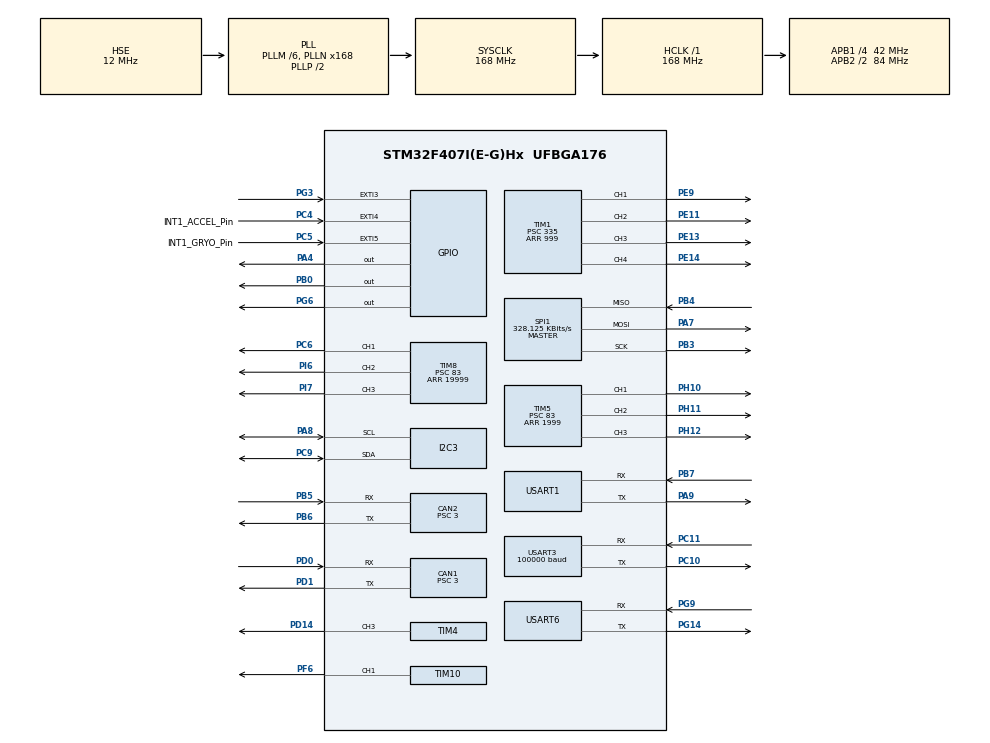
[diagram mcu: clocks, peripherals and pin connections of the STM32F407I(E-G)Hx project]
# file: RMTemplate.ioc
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CAN1.BS1=CAN_BS1_10TQ
CAN1.BS2=CAN_BS2_3TQ
CAN1.CalculateBaudRate=1000000
CAN1.CalculateTimeBit=1000
CAN1.CalculateTimeQuantum=71.42857142857143
CAN1.Prescaler=3
CAN2.BS1=CAN_BS1_10TQ
CAN2.BS2=CAN_BS2_3TQ
CAN2.CalculateBaudRate=1000000
CAN2.CalculateTimeBit=1000
CAN2.CalculateTimeQuantum=71.42857142857143
CAN2.Prescaler=3
Dma.Request0=USART3_RX
Dma.Request1=USART1_TX
Dma.Request2=USART1_RX
Dma.Request3=USART6_RX
Dma.Request4=USART6_TX
Dma.Request5=TIM1_CH1
Dma.Request6=TIM8_CH1/CH2/CH3
Dma.Request7=TIM4_CH3
Dma.Request8=TIM5_CH1
Dma.Request9=TIM5_CH2
Dma.TIM1_CH1.5.Direction=DMA_PERIPH_TO_MEMORY
Dma.TIM1_CH1.5.FIFOMode=DMA_FIFOMODE_DISABLE
Dma.TIM1_CH1.5.Instance=DMA2_Stream3
Dma.TIM1_CH1.5.MemDataAlignment=DMA_MDATAALIGN_HALFWORD
Dma.TIM1_CH1.5.MemInc=DMA_MINC_ENABLE
Dma.TIM1_CH1.5.Mode=DMA_NORMAL
Dma.TIM1_CH1.5.PeriphDataAlignment=DMA_PDATAALIGN_HALFWORD
Dma.TIM1_CH1.5.PeriphInc=DMA_PINC_DISABLE
Dma.TIM1_CH1.5.Priority=DMA_PRIORITY_LOW
Dma.TIM4_CH3.7.Direction=DMA_PERIPH_TO_MEMORY
Dma.TIM4_CH3.7.FIFOMode=DMA_FIFOMODE_DISABLE
Dma.TIM4_CH3.7.Instance=DMA1_Stream7
Dma.TIM4_CH3.7.MemDataAlignment=DMA_MDATAALIGN_HALFWORD
Dma.TIM4_CH3.7.MemInc=DMA_MINC_ENABLE
Dma.TIM4_CH3.7.Mode=DMA_NORMAL
Dma.TIM4_CH3.7.PeriphDataAlignment=DMA_PDATAALIGN_HALFWORD
Dma.TIM4_CH3.7.PeriphInc=DMA_PINC_DISABLE
Dma.TIM4_CH3.7.Priority=DMA_PRIORITY_LOW
Dma.TIM5_CH1.8.Direction=DMA_PERIPH_TO_MEMORY
Dma.TIM5_CH1.8.FIFOMode=DMA_FIFOMODE_DISABLE
Dma.TIM5_CH1.8.Instance=DMA1_Stream2
Dma.TIM5_CH1.8.MemDataAlignment=DMA_MDATAALIGN_WORD
Dma.TIM5_CH1.8.MemInc=DMA_MINC_ENABLE
Dma.TIM5_CH1.8.Mode=DMA_NORMAL
Dma.TIM5_CH1.8.PeriphDataAlignment=DMA_PDATAALIGN_WORD
Dma.TIM5_CH1.8.PeriphInc=DMA_PINC_DISABLE
Dma.TIM5_CH1.8.Priority=DMA_PRIORITY_LOW
Dma.TIM5_CH2.9.Direction=DMA_PERIPH_TO_MEMORY
Dma.TIM5_CH2.9.FIFOMode=DMA_FIFOMODE_DISABLE
Dma.TIM5_CH2.9.Instance=DMA1_Stream4
Dma.TIM5_CH2.9.MemDataAlignment=DMA_MDATAALIGN_WORD
Dma.TIM5_CH2.9.MemInc=DMA_MINC_ENABLE
Dma.TIM5_CH2.9.Mode=DMA_NORMAL
Dma.TIM5_CH2.9.PeriphDataAlignment=DMA_PDATAALIGN_WORD
Dma.TIM5_CH2.9.PeriphInc=DMA_PINC_DISABLE
Dma.TIM5_CH2.9.Priority=DMA_PRIORITY_LOW
Dma.TIM8_CH1/CH2/CH3.6.Direction=DMA_PERIPH_TO_MEMORY
Dma.TIM8_CH1/CH2/CH3.6.FIFOMode=DMA_FIFOMODE_DISABLE
Dma.TIM8_CH1/CH2/CH3.6.Instance=DMA2_Stream2
Dma.TIM8_CH1/CH2/CH3.6.MemDataAlignment=DMA_MDATAALIGN_HALFWORD
Dma.TIM8_CH1/CH2/CH3.6.MemInc=DMA_MINC_ENABLE
Dma.TIM8_CH1/CH2/CH3.6.Mode=DMA_NORMAL
Dma.TIM8_CH1/CH2/CH3.6.PeriphDataAlignment=DMA_PDATAALIGN_HALFWORD
Dma.TIM8_CH1/CH2/CH3.6.PeriphInc=DMA_PINC_DISABLE
Dma.TIM8_CH1/CH2/CH3.6.Priority=DMA_PRIORITY_LOW
Dma.USART1_RX.2.Direction=DMA_PERIPH_TO_MEMORY
Dma.USART1_RX.2.FIFOMode=DMA_FIFOMODE_DISABLE
Dma.USART1_RX.2.Instance=DMA2_Stream5
Dma.USART1_RX.2.MemDataAlignment=DMA_MDATAALIGN_BYTE
Dma.USART1_RX.2.MemInc=DMA_MINC_ENABLE
Dma.USART1_RX.2.Mode=DMA_NORMAL
Dma.USART1_RX.2.PeriphDataAlignment=DMA_PDATAALIGN_BYTE
Dma.USART1_RX.2.PeriphInc=DMA_PINC_DISABLE
Dma.USART1_RX.2.Priority=DMA_PRIORITY_VERY_HIGH
Dma.USART1_TX.1.Direction=DMA_MEMORY_TO_PERIPH
Dma.USART1_TX.1.FIFOMode=DMA_FIFOMODE_DISABLE
Dma.USART1_TX.1.Instance=DMA2_Stream7
Dma.USART1_TX.1.MemDataAlignment=DMA_MDATAALIGN_BYTE
Dma.USART1_TX.1.MemInc=DMA_MINC_ENABLE
Dma.USART1_TX.1.Mode=DMA_NORMAL
Dma.USART1_TX.1.PeriphDataAlignment=DMA_PDATAALIGN_BYTE
Dma.USART1_TX.1.PeriphInc=DMA_PINC_DISABLE
Dma.USART1_TX.1.Priority=DMA_PRIORITY_VERY_HIGH
Dma.USART3_RX.0.Direction=DMA_PERIPH_TO_MEMORY
Dma.USART3_RX.0.FIFOMode=DMA_FIFOMODE_DISABLE
Dma.USART3_RX.0.Instance=DMA1_Stream1
Dma.USART3_RX.0.MemDataAlignment=DMA_MDATAALIGN_BYTE
Dma.USART3_RX.0.MemInc=DMA_MINC_ENABLE
Dma.USART3_RX.0.Mode=DMA_CIRCULAR
Dma.USART3_RX.0.PeriphDataAlignment=DMA_PDATAALIGN_BYTE
Dma.USART3_RX.0.PeriphInc=DMA_PINC_DISABLE
Dma.USART3_RX.0.Priority=DMA_PRIORITY_VERY_HIGH
Dma.USART6_RX.3.Direction=DMA_PERIPH_TO_MEMORY
Dma.USART6_RX.3.FIFOMode=DMA_FIFOMODE_DISABLE
Dma.USART6_RX.3.Instance=DMA2_Stream1
Dma.USART6_RX.3.MemDataAlignment=DMA_MDATAALIGN_BYTE
Dma.USART6_RX.3.MemInc=DMA_MINC_ENABLE
Dma.USART6_RX.3.Mode=DMA_NORMAL
Dma.USART6_RX.3.PeriphDataAlignment=DMA_PDATAALIGN_BYTE
Dma.USART6_RX.3.PeriphInc=DMA_PINC_DISABLE
Dma.USART6_RX.3.Priority=DMA_PRIORITY_VERY_HIGH
Dma.USART6_TX.4.Direction=DMA_MEMORY_TO_PERIPH
Dma.USART6_TX.4.FIFOMode=DMA_FIFOMODE_DISABLE
Dma.USART6_TX.4.Instance=DMA2_Stream6
Dma.USART6_TX.4.MemDataAlignment=DMA_MDATAALIGN_BYTE
Dma.USART6_TX.4.MemInc=DMA_MINC_ENABLE
Dma.USART6_TX.4.Mode=DMA_NORMAL
Dma.USART6_TX.4.PeriphDataAlignment=DMA_PDATAALIGN_BYTE
Dma.USART6_TX.4.PeriphInc=DMA_PINC_DISABLE
Dma.USART6_TX.4.Priority=DMA_PRIORITY_VERY_HIGH
FREERTOS.INCLUDE_pcTaskGetTaskName=1
FREERTOS.INCLUDE_xTaskGetHandle=1
FREERTOS.Tasks01=defaultTask,32,1024,TaskMain,Default,NULL,Dynamic,NULL,NULL;chassisTask,40,1024,TaskChassis,Default,NULL,Dynamic,NULL,NULL;IMUtempPIDtask,24,512,imu_temp_control_task,As weak,NULL,Dynamic,NULL,NULL;turretTask,24,1024,TaskTurret,Default,NULL,Dynamic,NULL,NULL
FREERTOS.configUSE_NEWLIB_REENTRANT=1
I2C3.I2C_Mode=I2C_Fast
Mcu.Family=STM32F4
Mcu.Name=STM32F407I(E-G)Hx
Mcu.Package=UFBGA176
NVIC.CAN1_RX0_IRQn=true\:5\:0\:false\:false\:true\:true\:true\:true\:true
NVIC.CAN2_RX0_IRQn=true\:5\:0\:false\:false\:true\:true\:true\:true\:true
NVIC.DMA1_Stream1_IRQn=true\:5\:0\:false\:false\:true\:true\:false\:true\:true
NVIC.DMA1_Stream2_IRQn=true\:5\:0\:false\:false\:true\:true\:false\:true\:true
NVIC.DMA1_Stream4_IRQn=true\:5\:0\:false\:false\:true\:true\:false\:true\:true
NVIC.DMA1_Stream7_IRQn=true\:5\:0\:false\:false\:true\:true\:false\:true\:true
NVIC.DMA2_Stream1_IRQn=true\:5\:0\:false\:false\:true\:true\:false\:true\:true
NVIC.DMA2_Stream2_IRQn=true\:5\:0\:false\:false\:true\:true\:false\:true\:true
NVIC.DMA2_Stream3_IRQn=true\:5\:0\:false\:false\:true\:true\:false\:true\:true
NVIC.DMA2_Stream5_IRQn=true\:5\:0\:false\:false\:true\:false\:false\:true\:true
NVIC.DMA2_Stream6_IRQn=true\:5\:0\:false\:false\:true\:true\:false\:true\:true
NVIC.DMA2_Stream7_IRQn=true\:5\:0\:false\:false\:true\:true\:false\:true\:true
NVIC.EXTI3_IRQn=true\:5\:0\:false\:false\:true\:true\:true\:true\:true
NVIC.EXTI4_IRQn=true\:5\:0\:false\:false\:true\:true\:true\:true\:true
NVIC.PriorityGroup=NVIC_PRIORITYGROUP_4
NVIC.USART1_IRQn=true\:5\:0\:false\:false\:true\:true\:true\:true\:true
NVIC.USART3_IRQn=true\:5\:0\:false\:false\:false\:true\:true\:true\:true
NVIC.USART6_IRQn=true\:5\:0\:false\:false\:true\:true\:true\:true\:true
PA13.Mode=Serial_Wire
PA13.Signal=SYS_JTMS-SWDIO
PA14.Mode=Serial_Wire
PA14.Signal=SYS_JTCK-SWCLK
PA4.Signal=GPIO_Output
PA7.Mode=Full_Duplex_Master
PA7.Signal=SPI1_MOSI
PA8.Mode=I2C
PA8.Signal=I2C3_SCL
PA9.Mode=Asynchronous
PA9.Signal=USART1_TX
PB0.Signal=GPIO_Output
PB3.Mode=Full_Duplex_Master
PB3.Signal=SPI1_SCK
PB4.Mode=Full_Duplex_Master
PB4.Signal=SPI1_MISO
PB5.Mode=CAN_Activate
PB5.Signal=CAN2_RX
PB6.Mode=CAN_Activate
PB6.Signal=CAN2_TX
PB7.Mode=Asynchronous
PB7.Signal=USART1_RX
PC10.Mode=Asynchronous
PC10.Signal=USART3_TX
PC11.Mode=Asynchronous
PC11.Signal=USART3_RX
PC4.GPIO_Label=INT1_ACCEL_Pin
PC4.Signal=GPXTI4
PC5.GPIO_Label=INT1_GRYO_Pin
PC5.Signal=GPXTI5
PC6.Signal=S_TIM8_CH1
PC9.Mode=I2C
PC9.Signal=I2C3_SDA
PD0.Mode=CAN_Activate
PD0.Signal=CAN1_RX
PD1.Mode=CAN_Activate
PD1.Signal=CAN1_TX
PD14.Signal=S_TIM4_CH3
PE11.Signal=S_TIM1_CH2
PE13.Signal=S_TIM1_CH3
PE14.Signal=S_TIM1_CH4
PE9.Signal=S_TIM1_CH1
PF6.GPIO_PuPd=GPIO_PULLUP
PF6.GPIO_Speed=GPIO_SPEED_FREQ_HIGH
PF6.Signal=S_TIM10_CH1
PG14.Mode=Asynchronous
PG14.Signal=USART6_TX
PG3.Signal=GPXTI3
PG6.Signal=GPIO_Output
PG9.Mode=Asynchronous
PG9.Signal=USART6_RX
PH0-OSC_IN.Mode=HSE-External-Oscillator
PH0-OSC_IN.Signal=RCC_OSC_IN
PH1-OSC_OUT.Mode=HSE-External-Oscillator
PH1-OSC_OUT.Signal=RCC_OSC_OUT
PH10.Signal=S_TIM5_CH1
PH11.Signal=S_TIM5_CH2
PH12.Signal=S_TIM5_CH3
PI6.Signal=S_TIM8_CH2
PI7.Signal=S_TIM8_CH3
ProjectManager.HeapSize=0x200
ProjectManager.StackSize=0x400
ProjectManager.TargetToolchain=STM32CubeIDE
RCC.48MHZClocksFreq_Value=84000000
RCC.AHBFreq_Value=168000000
RCC.APB1CLKDivider=RCC_HCLK_DIV4
RCC.APB1Freq_Value=42000000
RCC.APB1TimFreq_Value=84000000
RCC.APB2CLKDivider=RCC_HCLK_DIV2
RCC.APB2Freq_Value=84000000
RCC.APB2TimFreq_Value=168000000
RCC.CortexFreq_Value=168000000
RCC.EnbaleCSS=true
RCC.HCLKFreq_Value=168000000
RCC.HSE_VALUE=12000000
RCC.HSI_VALUE=16000000
RCC.LSE_VALUE=32768
RCC.PLLM=6
RCC.PLLN=168
RCC.PLLSourceVirtual=RCC_PLLSOURCE_HSE
RCC.SYSCLKFreq_VALUE=168000000
RCC.SYSCLKSource=RCC_SYSCLKSOURCE_PLLCLK
RCC.VCOOutputFreq_Value=336000000
SH.S_TIM10_CH1.0=TIM10_CH1,PWM Generation1 CH1
SH.S_TIM1_CH1.0=TIM1_CH1,PWM Generation1 CH1
SH.S_TIM1_CH2.0=TIM1_CH2,PWM Generation2 CH2
SH.S_TIM1_CH3.0=TIM1_CH3,PWM Generation3 CH3
SH.S_TIM1_CH4.0=TIM1_CH4,PWM Generation4 CH4
SH.S_TIM4_CH3.0=TIM4_CH3,PWM Generation3 CH3
SH.S_TIM5_CH1.0=TIM5_CH1,PWM Generation1 CH1
SH.S_TIM5_CH2.0=TIM5_CH2,PWM Generation2 CH2
SH.S_TIM5_CH3.0=TIM5_CH3,PWM Generation3 CH3
SH.S_TIM8_CH1.0=TIM8_CH1,PWM Generation1 CH1
SH.S_TIM8_CH2.0=TIM8_CH2,PWM Generation2 CH2
SH.S_TIM8_CH3.0=TIM8_CH3,PWM Generation3 CH3
SPI1.BaudRatePrescaler=SPI_BAUDRATEPRESCALER_256
SPI1.CLKPhase=SPI_PHASE_2EDGE
SPI1.CLKPolarity=SPI_POLARITY_HIGH
SPI1.CalculateBaudRate=328.125 KBits/s
SPI1.Direction=SPI_DIRECTION_2LINES
SPI1.Mode=SPI_MODE_MASTER
SPI1.VirtualType=VM_MASTER
TIM1.AutoReloadPreload=TIM_AUTORELOAD_PRELOAD_DISABLE
TIM1.Channel-PWM\ Generation1\ CH1=TIM_CHANNEL_1
TIM1.Channel-PWM\ Generation2\ CH2=TIM_CHANNEL_2
TIM1.Channel-PWM\ Generation3\ CH3=TIM_CHANNEL_3
TIM1.Channel-PWM\ Generation4\ CH4=TIM_CHANNEL_4
TIM1.Period=999
TIM1.Prescaler=335
TIM1.Pulse-PWM\ Generation1\ CH1=0
TIM10.Channel=TIM_CHANNEL_1
TIM10.Period=4999
TIM4.AutoReloadPreload=TIM_AUTORELOAD_PRELOAD_ENABLE
TIM4.Channel-PWM\ Generation3\ CH3=TIM_CHANNEL_3
TIM4.Period=249
TIM4.Prescaler=83
TIM4.Pulse-PWM\ Generation3\ CH3=10499
TIM5.Channel-PWM\ Generation1\ CH1=TIM_CHANNEL_1
TIM5.Channel-PWM\ Generation2\ CH2=TIM_CHANNEL_2
TIM5.Channel-PWM\ Generation3\ CH3=TIM_CHANNEL_3
TIM5.Period=1999
TIM5.Prescaler=83
TIM8.AutoReloadPreload=TIM_AUTORELOAD_PRELOAD_ENABLE
TIM8.Channel-PWM\ Generation1\ CH1=TIM_CHANNEL_1
TIM8.Channel-PWM\ Generation2\ CH2=TIM_CHANNEL_2
TIM8.Channel-PWM\ Generation3\ CH3=TIM_CHANNEL_3
TIM8.Period=19999
TIM8.Prescaler=83
USART1.VirtualMode=VM_ASYNC
USART3.BaudRate=100000
USART3.Parity=PARITY_EVEN
USART3.VirtualMode=VM_ASYNC
USART6.VirtualMode=VM_ASYNC
VP_FREERTOS_VS_CMSIS_V2.Mode=CMSIS_V2
VP_TIM10_VS_ClockSourceINT.Mode=Enable_Timer
VP_TIM4_VS_ClockSourceINT.Mode=Internal
board=custom

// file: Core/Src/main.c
/* USER CODE BEGIN Header */
/**
  ******************************************************************************
  * @file           : main.c
  * @brief          : Main program body
  ******************************************************************************
  * @attention
  *
  * Copyright (c) 2024 STMicroelectronics.
  * All rights reserved.
  *
  * This software is licensed under terms that can be found in the LICENSE file
  * in the root directory of this software component.
  * If no LICENSE file comes with this software, it is provided AS-IS.
  *
  ******************************************************************************
  */
/* USER CODE END Header */
#include "main.h"
#include "cmsis_os.h"

/* USER CODE BEGIN Includes */
#include "CAN_receive.h"
#include "bsp_can.h"
#include "remote_control.h"
#include "bsp_rc.h"
#include "UART.h"
#include "stdio.h"
#include "stdarg.h"
#include "string.h"
#include "BMI088driver.h"
#include "pid.h"
#include "bsp_imu_pwm.h"
#include "ist8310driver.h"
#include "math.h"
#include "ctrl_handling.h"
#include "pwm.h"
/* USER CODE END Includes */

CAN_HandleTypeDef hcan1;
CAN_HandleTypeDef hcan2;

I2C_HandleTypeDef hi2c3;

SPI_HandleTypeDef hspi1;

TIM_HandleTypeDef htim1;
TIM_HandleTypeDef htim4;
TIM_HandleTypeDef htim5;
TIM_HandleTypeDef htim8;
TIM_HandleTypeDef htim10;
DMA_HandleTypeDef hdma_tim1_ch1;
DMA_HandleTypeDef hdma_tim4_ch3;
DMA_HandleTypeDef hdma_tim5_ch1;
DMA_HandleTypeDef hdma_tim5_ch2;
DMA_HandleTypeDef hdma_tim8_ch1_ch2_ch3;

UART_HandleTypeDef huart1;
UART_HandleTypeDef huart3;
UART_HandleTypeDef huart6;
DMA_HandleTypeDef hdma_usart1_tx;
DMA_HandleTypeDef hdma_usart1_rx;
DMA_HandleTypeDef hdma_usart3_rx;
DMA_HandleTypeDef hdma_usart6_rx;
DMA_HandleTypeDef hdma_usart6_tx;

/* Definitions for defaultTask */
osThreadId_t defaultTaskHandle;
const osThreadAttr_t defaultTask_attributes = {
  .name = "defaultTask",
  .stack_size = 1024 * 4,
  .priority = (osPriority_t) osPriorityAboveNormal,
};
/* Definitions for chassisTask */
osThreadId_t chassisTaskHandle;
const osThreadAttr_t chassisTask_attributes = {
  .name = "chassisTask",
  .stack_size = 1024 * 4,
  .priority = (osPriority_t) osPriorityHigh,
};
/* Definitions for IMUtempPIDtask */
osThreadId_t IMUtempPIDtaskHandle;
const osThreadAttr_t IMUtempPIDtask_attributes = {
  .name = "IMUtempPIDtask",
  .stack_size = 512 * 4,
  .priority = (osPriority_t) osPriorityNormal,
};
/* Definitions for turretTask */
osThreadId_t turretTaskHandle;
const osThreadAttr_t turretTask_attributes = {
  .name = "turretTask",
  .stack_size = 1024 * 4,
  .priority = (osPriority_t) osPriorityNormal,
};
/* USER CODE BEGIN PV */
const RC_ctrl_t *local_rc_ctrl;

PID_preset_t chassisPreset = {3.6, 0.015, 4.2};  //0.8f, 0.025f, 0.95f   {1.6, 0.045, 0.10}; 32 0.42
PID_preset_t yawPresetCurrentRPM = {46, 10.0, 16.4};
PID_preset_t yawPresetVoltageRPM = {50, 8.0, 2.0};
PID_preset_t yawPresetCurrentPosition = {12, 1, 0.0};
PID_preset_t yawPresetVoltagePosition = {36, 0.3, 0.0};
PID_preset_t indexerPreset = {1.1f, 0.02f, -2.4f};
PID_preset_t shooterPreset = {1.20f, 0.12f, 1.60f};
PID_preset_t powerPreset = {0, 0.000000000001, 0};
PID_preset_t customPreset = {0, 0, 0};
PID_preset_t DONUTMOTOR = {50, 8.0, 2.0}; // 46, 10, 16.4

int target = 2000;

can_msg_id_e boardID = CAN_b2b_B_ID;               // remember to change the board ID, board A - chassis, board B - Pitch axis

chassis_motor_config chassis = {{1,2,3,4,0,0,0,0}};
chassis_motor_RPM chassisTargetRPM = {{0,0,0,0,0,0,0,0}};
chassis_motor_current chassisTargetCurrent = {{0,0,0,0,0,0,0,0}};

extern game_status_t game_status;
extern power_heat_data_t power_heat_data;
extern robot_status_t robot_status;
extern b2b_motorCtrl_t b2bMotorCtrl;
extern b2b_gyro_t b2bGyro;
extern pc_control_t pc_control;
extern int8_t whichPWMisOn[11];

float calcChassisPower = 0;

/* USER CODE END PV */

void SystemClock_Config(void);
static void MX_GPIO_Init(void);
static void MX_DMA_Init(void);
static void MX_CAN1_Init(void);
static void MX_CAN2_Init(void);
static void MX_SPI1_Init(void);
static void MX_TIM4_Init(void);
static void MX_USART1_UART_Init(void);
static void MX_USART6_UART_Init(void);
static void MX_TIM1_Init(void);
static void MX_TIM8_Init(void);
static void MX_USART3_UART_Init(void);
static void MX_TIM10_Init(void);
static void MX_I2C3_Init(void);
static void MX_TIM5_Init(void);
void TaskMain(void *argument);
void TaskChassis(void *argument);
void imu_temp_control_task(void *argument);
void TaskTurret(void *argument);

int main(void)
{

  /* MCU Configuration--------------------------------------------------------*/

  /* Reset of all peripherals, Initializes the Flash interface and the Systick. */
  HAL_Init();

  /* Configure the system clock */
  SystemClock_Config();

  /* Initialize all configured peripherals */
  MX_GPIO_Init();
  MX_DMA_Init();
  MX_CAN1_Init();
  MX_CAN2_Init();
  MX_SPI1_Init();
  MX_TIM4_Init();
  MX_USART1_UART_Init();
  MX_USART6_UART_Init();
  MX_TIM1_Init();
  MX_TIM8_Init();
  MX_USART3_UART_Init();
  MX_TIM10_Init();
  MX_I2C3_Init();
  MX_TIM5_Init();
  /* USER CODE BEGIN 2 */
  can_filter_init();
  remote_control_init();
  usart_Init();
  local_rc_ctrl = get_remote_control_point();

  //__HAL_UART_ENABLE_IT(&huart1,UART_IT_IDLE);
  /* USER CODE END 2 */
  PWMInit(&htim1, &htim4, &htim5, &htim8);
  /* Init scheduler */
  osKernelInitialize();

  /* Create the thread(s) */
  /* creation of defaultTask */
  defaultTaskHandle = osThreadNew(TaskMain, NULL, &defaultTask_attributes);

  /* creation of chassisTask */
  chassisTaskHandle = osThreadNew(TaskChassis, NULL, &chassisTask_attributes);

  /* creation of IMUtempPIDtask */
  IMUtempPIDtaskHandle = osThreadNew(imu_temp_control_task, NULL, &IMUtempPIDtask_attributes);

  /* creation of turretTask */
  turretTaskHandle = osThreadNew(TaskTurret, NULL, &turretTask_attributes);

  /* Start scheduler */
  osKernelStart();

  /* We should never get here as control is now taken by the scheduler */

  /* Infinite loop */
  while (1)
  {

  }
}

void SystemClock_Config(void)
{
  RCC_OscInitTypeDef RCC_OscInitStruct = {0};
  RCC_ClkInitTypeDef RCC_ClkInitStruct = {0};

  /** Configure the main internal regulator output voltage
  */
  __HAL_RCC_PWR_CLK_ENABLE();
  __HAL_PWR_VOLTAGESCALING_CONFIG(PWR_REGULATOR_VOLTAGE_SCALE1);

  /** Initializes the RCC Oscillators according to the specified parameters
  * in the RCC_OscInitTypeDef structure.
  */
  RCC_OscInitStruct.OscillatorType = RCC_OSCILLATORTYPE_HSE;
  RCC_OscInitStruct.HSEState = RCC_HSE_ON;
  RCC_OscInitStruct.PLL.PLLState = RCC_PLL_ON;
  RCC_OscInitStruct.PLL.PLLSource = RCC_PLLSOURCE_HSE;
  RCC_OscInitStruct.PLL.PLLM = 6;
  RCC_OscInitStruct.PLL.PLLN = 168;
  RCC_OscInitStruct.PLL.PLLP = RCC_PLLP_DIV2;
  RCC_OscInitStruct.PLL.PLLQ = 4;
  if (HAL_RCC_OscConfig(&RCC_OscInitStruct) != HAL_OK)
  {
    Error_Handler();
  }

  /** Initializes the CPU, AHB and APB buses clocks
  */
  RCC_ClkInitStruct.ClockType = RCC_CLOCKTYPE_HCLK|RCC_CLOCKTYPE_SYSCLK
                              |RCC_CLOCKTYPE_PCLK1|RCC_CLOCKTYPE_PCLK2;
  RCC_ClkInitStruct.SYSCLKSource = RCC_SYSCLKSOURCE_PLLCLK;
  RCC_ClkInitStruct.AHBCLKDivider = RCC_SYSCLK_DIV1;
  RCC_ClkInitStruct.APB1CLKDivider = RCC_HCLK_DIV4;
  RCC_ClkInitStruct.APB2CLKDivider = RCC_HCLK_DIV2;

  if (HAL_RCC_ClockConfig(&RCC_ClkInitStruct, FLASH_LATENCY_5) != HAL_OK)
  {
    Error_Handler();
  }

  /** Enables the Clock Security System
  */
  HAL_RCC_EnableCSS();
}

static void MX_CAN1_Init(void)
{

  hcan1.Instance = CAN1;
  hcan1.Init.Prescaler = 3;
  hcan1.Init.Mode = CAN_MODE_NORMAL;
  hcan1.Init.SyncJumpWidth = CAN_SJW_1TQ;
  hcan1.Init.TimeSeg1 = CAN_BS1_10TQ;
  hcan1.Init.TimeSeg2 = CAN_BS2_3TQ;
  hcan1.Init.TimeTriggeredMode = DISABLE;
  hcan1.Init.AutoBusOff = DISABLE;
  hcan1.Init.AutoWakeUp = DISABLE;
  hcan1.Init.AutoRetransmission = DISABLE;
  hcan1.Init.ReceiveFifoLocked = DISABLE;
  hcan1.Init.TransmitFifoPriority = DISABLE;
  if (HAL_CAN_Init(&hcan1) != HAL_OK)
  {
    Error_Handler();
  }

}

static void MX_CAN2_Init(void)
{

  hcan2.Instance = CAN2;
  hcan2.Init.Prescaler = 3;
  hcan2.Init.Mode = CAN_MODE_NORMAL;
  hcan2.Init.SyncJumpWidth = CAN_SJW_1TQ;
  hcan2.Init.TimeSeg1 = CAN_BS1_10TQ;
  hcan2.Init.TimeSeg2 = CAN_BS2_3TQ;
  hcan2.Init.TimeTriggeredMode = DISABLE;
  hcan2.Init.AutoBusOff = DISABLE;
  hcan2.Init.AutoWakeUp = DISABLE;
  hcan2.Init.AutoRetransmission = DISABLE;
  hcan2.Init.ReceiveFifoLocked = DISABLE;
  hcan2.Init.TransmitFifoPriority = DISABLE;
  if (HAL_CAN_Init(&hcan2) != HAL_OK)
  {
    Error_Handler();
  }

}

static void MX_I2C3_Init(void)
{

  hi2c3.Instance = I2C3;
  hi2c3.Init.ClockSpeed = 400000;
  hi2c3.Init.DutyCycle = I2C_DUTYCYCLE_2;
  hi2c3.Init.OwnAddress1 = 0;
  hi2c3.Init.AddressingMode = I2C_ADDRESSINGMODE_7BIT;
  hi2c3.Init.DualAddressMode = I2C_DUALADDRESS_DISABLE;
  hi2c3.Init.OwnAddress2 = 0;
  hi2c3.Init.GeneralCallMode = I2C_GENERALCALL_DISABLE;
  hi2c3.Init.NoStretchMode = I2C_NOSTRETCH_DISABLE;
  if (HAL_I2C_Init(&hi2c3) != HAL_OK)
  {
    Error_Handler();
  }

}

static void MX_SPI1_Init(void)
{

  /* SPI1 parameter configuration*/
  hspi1.Instance = SPI1;
  hspi1.Init.Mode = SPI_MODE_MASTER;
  hspi1.Init.Direction = SPI_DIRECTION_2LINES;
  hspi1.Init.DataSize = SPI_DATASIZE_8BIT;
  hspi1.Init.CLKPolarity = SPI_POLARITY_HIGH;
  hspi1.Init.CLKPhase = SPI_PHASE_2EDGE;
  hspi1.Init.NSS = SPI_NSS_SOFT;
  hspi1.Init.BaudRatePrescaler = SPI_BAUDRATEPRESCALER_256;
  hspi1.Init.FirstBit = SPI_FIRSTBIT_MSB;
  hspi1.Init.TIMode = SPI_TIMODE_DISABLE;
  hspi1.Init.CRCCalculation = SPI_CRCCALCULATION_DISABLE;
  hspi1.Init.CRCPolynomial = 10;
  if (HAL_SPI_Init(&hspi1) != HAL_OK)
  {
    Error_Handler();
  }

}

static void MX_TIM1_Init(void)
{

  TIM_MasterConfigTypeDef sMasterConfig = {0};
  TIM_OC_InitTypeDef sConfigOC = {0};
  TIM_BreakDeadTimeConfigTypeDef sBreakDeadTimeConfig = {0};

  htim1.Instance = TIM1;
  htim1.Init.Prescaler = 335;
  htim1.Init.CounterMode = TIM_COUNTERMODE_UP;
  htim1.Init.Period = 999;
  htim1.Init.ClockDivision = TIM_CLOCKDIVISION_DIV1;
  htim1.Init.RepetitionCounter = 0;
  htim1.Init.AutoReloadPreload = TIM_AUTORELOAD_PRELOAD_DISABLE;
  if (HAL_TIM_PWM_Init(&htim1) != HAL_OK)
  {
    Error_Handler();
  }
  sMasterConfig.MasterOutputTrigger = TIM_TRGO_RESET;
  sMasterConfig.MasterSlaveMode = TIM_MASTERSLAVEMODE_DISABLE;
  if (HAL_TIMEx_MasterConfigSynchronization(&htim1, &sMasterConfig) != HAL_OK)
  {
    Error_Handler();
  }
  sConfigOC.OCMode = TIM_OCMODE_PWM1;
  sConfigOC.Pulse = 0;
  sConfigOC.OCPolarity = TIM_OCPOLARITY_HIGH;
  sConfigOC.OCNPolarity = TIM_OCNPOLARITY_HIGH;
  sConfigOC.OCFastMode = TIM_OCFAST_DISABLE;
  sConfigOC.OCIdleState = TIM_OCIDLESTATE_RESET;
  sConfigOC.OCNIdleState = TIM_OCNIDLESTATE_RESET;
  if (HAL_TIM_PWM_ConfigChannel(&htim1, &sConfigOC, TIM_CHANNEL_1) != HAL_OK)
  {
    Error_Handler();
  }
  if (HAL_TIM_PWM_ConfigChannel(&htim1, &sConfigOC, TIM_CHANNEL_2) != HAL_OK)
  {
    Error_Handler();
  }
  if (HAL_TIM_PWM_ConfigChannel(&htim1, &sConfigOC, TIM_CHANNEL_3) != HAL_OK)
  {
    Error_Handler();
  }
  if (HAL_TIM_PWM_ConfigChannel(&htim1, &sConfigOC, TIM_CHANNEL_4) != HAL_OK)
  {
    Error_Handler();
  }
  sBreakDeadTimeConfig.OffStateRunMode = TIM_OSSR_DISABLE;
  sBreakDeadTimeConfig.OffStateIDLEMode = TIM_OSSI_DISABLE;
  sBreakDeadTimeConfig.LockLevel = TIM_LOCKLEVEL_OFF;
  sBreakDeadTimeConfig.DeadTime = 0;
  sBreakDeadTimeConfig.BreakState = TIM_BREAK_DISABLE;
  sBreakDeadTimeConfig.BreakPolarity = TIM_BREAKPOLARITY_HIGH;
  sBreakDeadTimeConfig.AutomaticOutput = TIM_AUTOMATICOUTPUT_DISABLE;
  if (HAL_TIMEx_ConfigBreakDeadTime(&htim1, &sBreakDeadTimeConfig) != HAL_OK)
  {
    Error_Handler();
  }
  HAL_TIM_MspPostInit(&htim1);

}

static void MX_TIM4_Init(void)
{

  TIM_ClockConfigTypeDef sClockSourceConfig = {0};
  TIM_MasterConfigTypeDef sMasterConfig = {0};
  TIM_OC_InitTypeDef sConfigOC = {0};

  htim4.Instance = TIM4;
  htim4.Init.Prescaler = 83;
  htim4.Init.CounterMode = TIM_COUNTERMODE_UP;
  htim4.Init.Period = 249;
  htim4.Init.ClockDivision = TIM_CLOCKDIVISION_DIV1;
  htim4.Init.AutoReloadPreload = TIM_AUTORELOAD_PRELOAD_ENABLE;
  if (HAL_TIM_Base_Init(&htim4) != HAL_OK)
  {
    Error_Handler();
  }
  sClockSourceConfig.ClockSource = TIM_CLOCKSOURCE_INTERNAL;
  if (HAL_TIM_ConfigClockSource(&htim4, &sClockSourceConfig) != HAL_OK)
  {
    Error_Handler();
  }
  if (HAL_TIM_PWM_Init(&htim4) != HAL_OK)
  {
    Error_Handler();
  }
  sMasterConfig.MasterOutputTrigger = TIM_TRGO_RESET;
  sMasterConfig.MasterSlaveMode = TIM_MASTERSLAVEMODE_DISABLE;
  if (HAL_TIMEx_MasterConfigSynchronization(&htim4, &sMasterConfig) != HAL_OK)
  {
    Error_Handler();
  }
  sConfigOC.OCMode = TIM_OCMODE_PWM1;
  sConfigOC.Pulse = 10499;
  sConfigOC.OCPolarity = TIM_OCPOLARITY_HIGH;
  sConfigOC.OCFastMode = TIM_OCFAST_DISABLE;
  if (HAL_TIM_PWM_ConfigChannel(&htim4, &sConfigOC, TIM_CHANNEL_3) != HAL_OK)
  {
    Error_Handler();
  }
  HAL_TIM_MspPostInit(&htim4);

}

static void MX_TIM5_Init(void)
{

  TIM_MasterConfigTypeDef sMasterConfig = {0};
  TIM_OC_InitTypeDef sConfigOC = {0};

  htim5.Instance = TIM5;
  htim5.Init.Prescaler = 83;
  htim5.Init.CounterMode = TIM_COUNTERMODE_UP;
  htim5.Init.Period = 1999;
  htim5.Init.ClockDivision = TIM_CLOCKDIVISION_DIV1;
  htim5.Init.AutoReloadPreload = TIM_AUTORELOAD_PRELOAD_DISABLE;
  if (HAL_TIM_PWM_Init(&htim5) != HAL_OK)
  {
    Error_Handler();
  }
  sMasterConfig.MasterOutputTrigger = TIM_TRGO_RESET;
  sMasterConfig.MasterSlaveMode = TIM_MASTERSLAVEMODE_DISABLE;
  if (HAL_TIMEx_MasterConfigSynchronization(&htim5, &sMasterConfig) != HAL_OK)
  {
    Error_Handler();
  }
  sConfigOC.OCMode = TIM_OCMODE_PWM1;
  sConfigOC.Pulse = 0;
  sConfigOC.OCPolarity = TIM_OCPOLARITY_HIGH;
  sConfigOC.OCFastMode = TIM_OCFAST_DISABLE;
  if (HAL_TIM_PWM_ConfigChannel(&htim5, &sConfigOC, TIM_CHANNEL_1) != HAL_OK)
  {
    Error_Handler();
  }
  if (HAL_TIM_PWM_ConfigChannel(&htim5, &sConfigOC, TIM_CHANNEL_2) != HAL_OK)
  {
    Error_Handler();
  }
  if (HAL_TIM_PWM_ConfigChannel(&htim5, &sConfigOC, TIM_CHANNEL_3) != HAL_OK)
  {
    Error_Handler();
  }
  HAL_TIM_MspPostInit(&htim5);

}

static void MX_TIM8_Init(void)
{

  TIM_MasterConfigTypeDef sMasterConfig = {0};
  TIM_OC_InitTypeDef sConfigOC = {0};
  TIM_BreakDeadTimeConfigTypeDef sBreakDeadTimeConfig = {0};

  htim8.Instance = TIM8;
  htim8.Init.Prescaler = 83;
  htim8.Init.CounterMode = TIM_COUNTERMODE_UP;
  htim8.Init.Period = 19999;
  htim8.Init.ClockDivision = TIM_CLOCKDIVISION_DIV1;
  htim8.Init.RepetitionCounter = 0;
  htim8.Init.AutoReloadPreload = TIM_AUTORELOAD_PRELOAD_ENABLE;
  if (HAL_TIM_PWM_Init(&htim8) != HAL_OK)
  {
    Error_Handler();
  }
  sMasterConfig.MasterOutputTrigger = TIM_TRGO_RESET;
  sMasterConfig.MasterSlaveMode = TIM_MASTERSLAVEMODE_DISABLE;
  if (HAL_TIMEx_MasterConfigSynchronization(&htim8, &sMasterConfig) != HAL_OK)
  {
    Error_Handler();
  }
  sConfigOC.OCMode = TIM_OCMODE_PWM1;
  sConfigOC.Pulse = 0;
  sConfigOC.OCPolarity = TIM_OCPOLARITY_HIGH;
  sConfigOC.OCNPolarity = TIM_OCNPOLARITY_HIGH;
  sConfigOC.OCFastMode = TIM_OCFAST_DISABLE;
  sConfigOC.OCIdleState = TIM_OCIDLESTATE_RESET;
  sConfigOC.OCNIdleState = TIM_OCNIDLESTATE_RESET;
  if (HAL_TIM_PWM_ConfigChannel(&htim8, &sConfigOC, TIM_CHANNEL_1) != HAL_OK)
  {
    Error_Handler();
  }
  if (HAL_TIM_PWM_ConfigChannel(&htim8, &sConfigOC, TIM_CHANNEL_2) != HAL_OK)
  {
    Error_Handler();
  }
  if (HAL_TIM_PWM_ConfigChannel(&htim8, &sConfigOC, TIM_CHANNEL_3) != HAL_OK)
  {
    Error_Handler();
  }
  sBreakDeadTimeConfig.OffStateRunMode = TIM_OSSR_DISABLE;
  sBreakDeadTimeConfig.OffStateIDLEMode = TIM_OSSI_DISABLE;
  sBreakDeadTimeConfig.LockLevel = TIM_LOCKLEVEL_OFF;
  sBreakDeadTimeConfig.DeadTime = 0;
  sBreakDeadTimeConfig.BreakState = TIM_BREAK_DISABLE;
  sBreakDeadTimeConfig.BreakPolarity = TIM_BREAKPOLARITY_HIGH;
  sBreakDeadTimeConfig.AutomaticOutput = TIM_AUTOMATICOUTPUT_DISABLE;
  if (HAL_TIMEx_ConfigBreakDeadTime(&htim8, &sBreakDeadTimeConfig) != HAL_OK)
  {
    Error_Handler();
  }
  HAL_TIM_MspPostInit(&htim8);

}

static void MX_TIM10_Init(void)
{

  TIM_OC_InitTypeDef sConfigOC = {0};

  htim10.Instance = TIM10;
  htim10.Init.Prescaler = 0;
  htim10.Init.CounterMode = TIM_COUNTERMODE_UP;
  htim10.Init.Period = 4999;
  htim10.Init.ClockDivision = TIM_CLOCKDIVISION_DIV1;
  htim10.Init.AutoReloadPreload = TIM_AUTORELOAD_PRELOAD_DISABLE;
  if (HAL_TIM_Base_Init(&htim10) != HAL_OK)
  {
    Error_Handler();
  }
  if (HAL_TIM_PWM_Init(&htim10) != HAL_OK)
  {
    Error_Handler();
  }
  sConfigOC.OCMode = TIM_OCMODE_PWM1;
  sConfigOC.Pulse = 0;
  sConfigOC.OCPolarity = TIM_OCPOLARITY_HIGH;
  sConfigOC.OCFastMode = TIM_OCFAST_DISABLE;
  if (HAL_TIM_PWM_ConfigChannel(&htim10, &sConfigOC, TIM_CHANNEL_1) != HAL_OK)
  {
    Error_Handler();
  }
  HAL_TIM_MspPostInit(&htim10);

}

static void MX_USART1_UART_Init(void)
{

  huart1.Instance = USART1;
  huart1.Init.BaudRate = 115200;
  huart1.Init.WordLength = UART_WORDLENGTH_8B;
  huart1.Init.StopBits = UART_STOPBITS_1;
  huart1.Init.Parity = UART_PARITY_NONE;
  huart1.Init.Mode = UART_MODE_TX_RX;
  huart1.Init.HwFlowCtl = UART_HWCONTROL_NONE;
  huart1.Init.OverSampling = UART_OVERSAMPLING_16;
  if (HAL_UART_Init(&huart1) != HAL_OK)
  {
    Error_Handler();
  }

}

static void MX_USART3_UART_Init(void)
{

  huart3.Instance = USART3;
  huart3.Init.BaudRate = 100000;
  huart3.Init.WordLength = UART_WORDLENGTH_8B;
  huart3.Init.StopBits = UART_STOPBITS_1;
  huart3.Init.Parity = UART_PARITY_EVEN;
  huart3.Init.Mode = UART_MODE_TX_RX;
  huart3.Init.HwFlowCtl = UART_HWCONTROL_NONE;
  huart3.Init.OverSampling = UART_OVERSAMPLING_16;
  if (HAL_UART_Init(&huart3) != HAL_OK)
  {
    Error_Handler();
  }

}

static void MX_USART6_UART_Init(void)
{

  huart6.Instance = USART6;
  huart6.Init.BaudRate = 115200;
  huart6.Init.WordLength = UART_WORDLENGTH_8B;
  huart6.Init.StopBits = UART_STOPBITS_1;
  huart6.Init.Parity = UART_PARITY_NONE;
  huart6.Init.Mode = UART_MODE_TX_RX;
  huart6.Init.HwFlowCtl = UART_HWCONTROL_NONE;
  huart6.Init.OverSampling = UART_OVERSAMPLING_16;
  if (HAL_UART_Init(&huart6) != HAL_OK)
  {
    Error_Handler();
  }

}

static void MX_DMA_Init(void)
{

  /* DMA controller clock enable */
  __HAL_RCC_DMA1_CLK_ENABLE();
  __HAL_RCC_DMA2_CLK_ENABLE();

  /* DMA interrupt init */
  /* DMA1_Stream1_IRQn interrupt configuration */
  HAL_NVIC_SetPriority(DMA1_Stream1_IRQn, 5, 0);
  HAL_NVIC_EnableIRQ(DMA1_Stream1_IRQn);
  /* DMA1_Stream2_IRQn interrupt configuration */
  HAL_NVIC_SetPriority(DMA1_Stream2_IRQn, 5, 0);
  HAL_NVIC_EnableIRQ(DMA1_Stream2_IRQn);
  /* DMA1_Stream4_IRQn interrupt configuration */
  HAL_NVIC_SetPriority(DMA1_Stream4_IRQn, 5, 0);
  HAL_NVIC_EnableIRQ(DMA1_Stream4_IRQn);
  /* DMA1_Stream7_IRQn interrupt configuration */
  HAL_NVIC_SetPriority(DMA1_Stream7_IRQn, 5, 0);
  HAL_NVIC_EnableIRQ(DMA1_Stream7_IRQn);
  /* DMA2_Stream1_IRQn interrupt configuration */
  HAL_NVIC_SetPriority(DMA2_Stream1_IRQn, 5, 0);
  HAL_NVIC_EnableIRQ(DMA2_Stream1_IRQn);
  /* DMA2_Stream2_IRQn interrupt configuration */
  HAL_NVIC_SetPriority(DMA2_Stream2_IRQn, 5, 0);
  HAL_NVIC_EnableIRQ(DMA2_Stream2_IRQn);
  /* DMA2_Stream3_IRQn interrupt configuration */
  HAL_NVIC_SetPriority(DMA2_Stream3_IRQn, 5, 0);
  HAL_NVIC_EnableIRQ(DMA2_Stream3_IRQn);
  /* DMA2_Stream5_IRQn interrupt configuration */
  HAL_NVIC_SetPriority(DMA2_Stream5_IRQn, 5, 0);
  HAL_NVIC_EnableIRQ(DMA2_Stream5_IRQn);
  /* DMA2_Stream6_IRQn interrupt configuration */
  HAL_NVIC_SetPriority(DMA2_Stream6_IRQn, 5, 0);
  HAL_NVIC_EnableIRQ(DMA2_Stream6_IRQn);
  /* DMA2_Stream7_IRQn interrupt configuration */
  HAL_NVIC_SetPriority(DMA2_Stream7_IRQn, 5, 0);
  HAL_NVIC_EnableIRQ(DMA2_Stream7_IRQn);

}

static void MX_GPIO_Init(void)
{
  GPIO_InitTypeDef GPIO_InitStruct = {0};

  /* GPIO Ports Clock Enable */
  __HAL_RCC_GPIOB_CLK_ENABLE();
  __HAL_RCC_GPIOG_CLK_ENABLE();
  __HAL_RCC_GPIOA_CLK_ENABLE();
  __HAL_RCC_GPIOD_CLK_ENABLE();
  __HAL_RCC_GPIOC_CLK_ENABLE();
  __HAL_RCC_GPIOI_CLK_ENABLE();
  __HAL_RCC_GPIOH_CLK_ENABLE();
  __HAL_RCC_GPIOF_CLK_ENABLE();
  __HAL_RCC_GPIOE_CLK_ENABLE();

  /*Configure GPIO pin Output Level */
  HAL_GPIO_WritePin(GPIOG, GPIO_PIN_6, GPIO_PIN_RESET);

  /*Configure GPIO pin Output Level */
  HAL_GPIO_WritePin(GPIOA, GPIO_PIN_4, GPIO_PIN_RESET);

  /*Configure GPIO pin Output Level */
  HAL_GPIO_WritePin(GPIOB, GPIO_PIN_0, GPIO_PIN_RESET);

  /*Configure GPIO pin : PG6 */
  GPIO_InitStruct.Pin = GPIO_PIN_6;
  GPIO_InitStruct.Mode = GPIO_MODE_OUTPUT_PP;
  GPIO_InitStruct.Pull = GPIO_NOPULL;
  GPIO_InitStruct.Speed = GPIO_SPEED_FREQ_LOW;
  HAL_GPIO_Init(GPIOG, &GPIO_InitStruct);

  /*Configure GPIO pin : PG3 */
  GPIO_InitStruct.Pin = GPIO_PIN_3;
  GPIO_InitStruct.Mode = GPIO_MODE_IT_RISING;
  GPIO_InitStruct.Pull = GPIO_NOPULL;
  HAL_GPIO_Init(GPIOG, &GPIO_InitStruct);

  /*Configure GPIO pin : PA4 */
  GPIO_InitStruct.Pin = GPIO_PIN_4;
  GPIO_InitStruct.Mode = GPIO_MODE_OUTPUT_PP;
  GPIO_InitStruct.Pull = GPIO_NOPULL;
  GPIO_InitStruct.Speed = GPIO_SPEED_FREQ_LOW;
  HAL_GPIO_Init(GPIOA, &GPIO_InitStruct);

  /*Configure GPIO pins : INT1_ACCEL_Pin_Pin INT1_GRYO_Pin_Pin */
  GPIO_InitStruct.Pin = INT1_ACCEL_Pin_Pin|INT1_GRYO_Pin_Pin;
  GPIO_InitStruct.Mode = GPIO_MODE_IT_RISING;
  GPIO_InitStruct.Pull = GPIO_NOPULL;
  HAL_GPIO_Init(GPIOC, &GPIO_InitStruct);

  /*Configure GPIO pin : PB0 */
  GPIO_InitStruct.Pin = GPIO_PIN_0;
  GPIO_InitStruct.Mode = GPIO_MODE_OUTPUT_PP;
  GPIO_InitStruct.Pull = GPIO_NOPULL;
  GPIO_InitStruct.Speed = GPIO_SPEED_FREQ_LOW;
  HAL_GPIO_Init(GPIOB, &GPIO_InitStruct);

  /* EXTI interrupt init*/
  HAL_NVIC_SetPriority(EXTI3_IRQn, 5, 0);
  HAL_NVIC_EnableIRQ(EXTI3_IRQn);

  HAL_NVIC_SetPriority(EXTI4_IRQn, 5, 0);
  HAL_NVIC_EnableIRQ(EXTI4_IRQn);

}

/* USER CODE BEGIN 4 */
int16_t positionPIDByMe(int16_t *prevDiff, int8_t *isNegativeRegion1, int8_t *previousRegion1, int16_t DifferenceBetweenCurrentAndWannabePosition, int16_t *sumI1, float kPu, float kIu, float kDu) {
	if (DifferenceBetweenCurrentAndWannabePosition >= 0) {
		*isNegativeRegion1 = -1;
	} else {
		*isNegativeRegion1 = 1;
	}
	if (*isNegativeRegion1 != *previousRegion1) {
		*sumI1 = 0;
	}
	*previousRegion1 = *isNegativeRegion1;
	*sumI1 += (int)((float)(DifferenceBetweenCurrentAndWannabePosition)*0.005f);
	int16_t PositionToGo = (int)(kPu*(float)(DifferenceBetweenCurrentAndWannabePosition));
	int16_t IntegralToGo = (int)(kIu*((float)(*sumI1)));
	int16_t DerivativeToGo = (int)((kDu)*((float)(DifferenceBetweenCurrentAndWannabePosition - *prevDiff))*(float)200);
	*prevDiff = DifferenceBetweenCurrentAndWannabePosition;
	return PositionToGo+IntegralToGo+DerivativeToGo;
}
/* USER CODE END 4 */

void TaskMain(void *argument)
{
  /* USER CODE BEGIN 5 */
  /* Infinite loop */
	// HAL_GPIO_WritePin(GPIOH, GPIO_PIN_10, 1);
	// __HAL_TIM_PRESCALER(&htim4, 2);
	// HAL_TIM_PWM_Start(&htim4, TIM_CHANNEL_3);
	// HAL_TIM_Base_Start(&htim4);
	if (BMI088_accel_init()) {
		// usart_printf("WARNING - BMI088 accelerometer init failed \r\n");
	}
	if (BMI088_gyro_init()) {
		// usart_printf("WARNING - BMI088 gyroscope init failed \r\n");
	}
	if (ist8310_init()) {
		// usart_printf("WARNING - IST8310 compass init failed \r\n");
	}
	// (htim5).Instance->CCR2=999;
	// osDelay(150);
	// __HAL_TIM_PRESCALER(&htim4, 0);
	// osDelay(150);
	// HAL_TIM_PWM_Stop(&htim4, TIM_CHANNEL_3);
	for(;;) {
		// HAL_GPIO_WritePin(GPIOH, GPIO_PIN_10, 0);
		//set_motor_voltage(5, 4000);

		// HAL_TIM_PWM_Start(&htim5, TIM_CHANNEL_2);

		// PWMOn(LED,1);
		PWMOutput(LED, 1, 500);
		PWMInitialize(LED, FR, 1, 0.9);
		// PWMTimerStarter();
		usart_printf("on\r\n");
		osDelay(500);
		//sendB2bData(CAN_b2b_A_ID, 1, 1, 1, 1);
		// HAL_GPIO_WritePin(GPIOH, GPIO_PIN_10, 1);
		//set_motor_voltage(5, -4000);
		// HAL_TIM_PWM_Stop(&htim5, TIM_CHANNEL_2);
		PWMOff(LED, 1);
		// PWMTimerStarter();
		usart_printf("off\r\n");
		osDelay(500);
		//sendB2bData(CAN_b2b_A_ID, 0, 0, 0, 0);
		//usart_printf("ACTIVE = %d \r\n", power_heat_data.chassis_power);
	}
  /* USER CODE END 5 */
}

void TaskChassis(void *argument)
{
  /* USER CODE BEGIN TaskChassis */
	/* USER CODE BEGIN TaskChassis */
	int16_t rcRPM[4] = {0,0,0,0};                              // maps rc percentage reading to motors, assuming we're running M3508s at max 469RPM
	int16_t rcPitch = 0;                                   // range: 3376 ~ 2132
	//int16_t targetRPM[4] = {0,0,0,0};
  /* Infinite loop */

	// Test Code
	/*
	HAL_TIM_Base_Start(&htim1);
	HAL_TIM_Base_Start(&htim4);
	HAL_TIM_PWM_Start(&htim1, TIM_CHANNEL_1);
	HAL_TIM_PWM_Start(&htim1, TIM_CHANNEL_2);
	HAL_TIM_PWM_Start(&htim4, TIM_CHANNEL_3);
	htim4.Instance->CCR3=0;
	*/

	int8_t motorOn = 0;
	int8_t switched = 0;
	int8_t shot1Round = 0;
	//int8_t RNC = 0;
	int16_t sumI1 =0;
	int16_t sumI2 =0;
	int16_t sumI3 =0;
	int16_t sumI4 =0;
	int8_t isNegativeRegion1 = 0;
	int8_t isNegativeRegion2 = 0;
	int8_t isNegativeRegion3 = 0;
	int8_t isNegativeRegion4 = 0;
	int8_t previousRegion1 = 0;
	int8_t previousRegion2 = 0;
	int8_t previousRegion3 = 0;
	int8_t previousRegion4 = 0;
	int16_t prevDiff1 = 0;
	int16_t prevDiff2 = 0;
	int16_t prevDiff3 = 0;
	int16_t prevDiff4 = 0;

	int16_t shooterMotor = 0;
	// int16_t pR = 0;
	//int8_t counter = 0;
	uint16_t testmotor = 6161;
	uint16_t pivoter = 0;
	double angle = 0;
	int16_t xJoystickDirection = 0;
	int16_t yJoystickDirection = 0;
	int16_t rotationOfChassis = 0;
	// Total Rotation is 1.25 times for 90degrees therefore motor has to rotate
	// PID onto this (This is the hypothetical orientation)
	int16_t chassisOrientation = 0;
	int16_t chassisPID = 0;
	int16_t rcVal2 = 0;

	int16_t randomOrientations[24] = {-380, -202, 462, -114, 240, -210, 150, 170, 248, 106, 118, 538, -260, -288, -120, 86, -264, 452, -592, 390, -410, 414, 54, -542};
	int16_t startingVal = 0;
	int8_t started = 0;
	uint8_t increment = 0;
	int16_t instancesCounter = 0;

	int16_t previousVal = 0;
	int32_t rotationalVal = 0;
	int16_t revolutions = 0;
	int8_t resetPerStart = 0;
	int32_t rotationTarget = 0;
	int32_t posForGunMotor = 0;
	int8_t burst = 3;

	int8_t customFiringModeSwitcher = 0;
	int8_t startedChecking = 0;
	int8_t switchedDown = 0;
	int8_t finalTHing = 0;
	int16_t counterForSwitching = 0;

	int16_t buzzLengthCounter = 0;
	int8_t beepingInProgress = 0;
	int8_t beeped = 1;

	int16_t rotationCompStab = 0;
	int16_t testTHing[11] = {0, 0, 0, 0, 0, 0, 0, 0, 0, 0, 0};

	/*
	float rotationPositionZ = 0;
	float rotationPositionY = 0;
	int8_t average = 5;
	int16_t averageY[average];
	for (int i = 0; i < average; i++) {
		averageY[i] = 0;
	}
	*/

	for(;;) {

		for (int i = 0; i < 4; i++) {
			rcRPM[i] = getRCchannel(i) * 13.645f;              // 13.645 = 469 / 187 / 660 * 3591, 660 = max reading in one direction
		}
		/*
		int arrayOfMOvement[2] = {0, 0};
		getKeyboardVelocity(arrayOfMOvement, 0.03, pc_control);
		rcRPM[0] = 0;
		rcRPM[1] = 0;
		rcRPM[2] = arrayOfMOvement[0];
		rcRPM[3] = arrayOfMOvement[1];
		*/
		rcPitch = getRCchannel(1) * 0.94f + 2754;
		int16_t leftDial = getRCchannel(4);

		int8_t chassisTurning = getRCswitch(1);

		float funnyKP = 0.022;
		float funnyKI = -0.02;
		float funnyKD = 0.00005;
		float rotationScalar = -540; //-540

		if (counterForSwitching > 200) {
			startedChecking = 0;
			switchedDown = 0;
			finalTHing = 0;
			counterForSwitching = 0;
		}

		if (startedChecking == 1) {
			counterForSwitching++;
		}

		int8_t movementUpOrDown = 5;
		if (increment == 18) {
			increment = 0;
		}

		if (instancesCounter > 100) {
			increment++;
			instancesCounter = 0;
		}

		if (chassisTurning == 1 && startedChecking == 0) {
			counterForSwitching = 0;
			startedChecking = 1;

		}
		if (chassisTurning == 3 && startedChecking == 1) {
			switchedDown = 1;
		}
		if (chassisTurning == 1 && startedChecking == 1 && switchedDown == 1) {
			finalTHing = 1;
		}

		if (chassisTurning == 3 && startedChecking == 1 && switchedDown == 1 && finalTHing == 1 && counterForSwitching < 200) {
			switchedDown = 0;
			startedChecking = 0;
			counterForSwitching = 0;
			finalTHing = 0;
			customFiringModeSwitcher++;
			beeped = 0;
			buzzLengthCounter = 0;

		}
		if (customFiringModeSwitcher > 2) {
			customFiringModeSwitcher = 0;
		}

		// usart_printf("$%d %d %d %d\r\n;",customFiringModeSwitcher, startedChecking, switchedDown, counterForSwitching);
		/*
		PWMOutput(LED, 3, 500);
		PWMOutput(Buzzer, 3, 1000);
		PWMOff(LED, 3);
		PWMOff(Buzzer, 3);
		*/
		PWMInitialize(Buzzer, 2, FR, 0.9);
		PWMInitialize(LED, FR, 3, 0.9);
		if (beeped == 0) {
			switch (customFiringModeSwitcher) {
			case 0:
				if ((buzzLengthCounter == 0)) {
					// HAL_TIM_PWM_Start(&htim4, TIM_CHANNEL_3);
					/*
					htim4.Instance->CCR3=150;
					HAL_GPIO_WritePin(GPIOH, GPIO_PIN_12, 1);
					*/
					PWMOutput(LED, 3, 500);
					PWMOutput(Buzzer, 3, 1000);
				}
				else if (buzzLengthCounter >=60) {
					// HAL_TIM_PWM_Stop(&htim4, TIM_CHANNEL_3);
					beeped = 1;
					/*
					htim4.Instance->CCR3=0;
					HAL_GPIO_WritePin(GPIOH, GPIO_PIN_12, 0);
					*/
					PWMOff(LED, 3);
					PWMOff(Buzzer, 3);
				}
				buzzLengthCounter++;
				break;
			case 1:
				if (buzzLengthCounter == 0) {
					// HAL_TIM_PWM_Start(&htim4, TIM_CHANNEL_3);
					/*
					htim4.Instance->CCR3=150;
					HAL_GPIO_WritePin(GPIOH, GPIO_PIN_12, 1);
					*/
					PWMOutput(LED, 3, 500);
					PWMOutput(Buzzer, 3, 1000);
				} else if (buzzLengthCounter >=12) {
					// HAL_TIM_PWM_Stop(&htim4, TIM_CHANNEL_3);
					beeped = 1;
					/*
					htim4.Instance->CCR3=0;
					HAL_GPIO_WritePin(GPIOH, GPIO_PIN_12, 0);
					*/
					PWMOff(LED, 3);
					PWMOff(Buzzer, 3);
				}
				buzzLengthCounter++;
				break;
			case 2:
				if ((buzzLengthCounter == 0) || (buzzLengthCounter == 30) || (buzzLengthCounter == 60)) {
					// HAL_TIM_PWM_Start(&htim4, TIM_CHANNEL_3);
					/*
					htim4.Instance->CCR3=150;
					HAL_GPIO_WritePin(GPIOH, GPIO_PIN_12, 1);
					*/
					PWMOutput(LED, 3, 500);
					PWMOutput(Buzzer, 3, 1000);
				} else if ((buzzLengthCounter == 15) || (buzzLengthCounter == 45)) {
					// HAL_TIM_PWM_Stop(&htim4, TIM_CHANNEL_3);
					/*
					htim4.Instance->CCR3=0;
					HAL_GPIO_WritePin(GPIOH, GPIO_PIN_12, 0);
					*/
					PWMOff(LED, 3);
					PWMOff(Buzzer, 3);
				} else if (buzzLengthCounter >=75) {
					// HAL_TIM_PWM_Stop(&htim4, TIM_CHANNEL_3);
					beeped = 1;
					/*
					htim4.Instance->CCR3=0;
					HAL_GPIO_WritePin(GPIOH, GPIO_PIN_12, 0);
					*/
					PWMOff(LED, 3);
					PWMOff(Buzzer, 3);
				}
				buzzLengthCounter++;
				break;
			}
		}

		switch (chassisTurning) {
		case 1:
			xJoystickDirection = rcRPM[2]*cos(angle) - rcRPM[3]*sin(angle);
			yJoystickDirection = rcRPM[2]*sin(angle) + rcRPM[3]*cos(angle);
			rotationOfChassis = rcRPM[0];

			started = 0;

			break;
		case 2:
			int8_t delta = 5;
			if (started == 0) {
				startingVal = 0;
				started = 1;
			}
			if (startingVal >= randomOrientations[increment]-delta && startingVal <= randomOrientations[increment]+delta) {
				instancesCounter++;
			} else if (startingVal > randomOrientations[increment]-delta) {
				startingVal -= movementUpOrDown;
			} else {
				startingVal += movementUpOrDown;
			}

			xJoystickDirection = rcRPM[2]*cos(angle) - rcRPM[3]*sin(angle);
			yJoystickDirection = rcRPM[2]*sin(angle) + rcRPM[3]*cos(angle);
			int16_t hypotheticalP = funnyKP*(startingVal - chassisOrientation);
			if (hypotheticalP >= 0) {
				isNegativeRegion3 = -1;
			} else {
				isNegativeRegion3 = 1;
			}
			if (hypotheticalP != previousRegion3) {
				sumI3 = 0;
			}
			previousRegion3 = hypotheticalP;
			sumI3 += (startingVal - chassisOrientation)*0.005;
			int16_t hypotheticalI = funnyKI*(sumI3);
			int16_t hypotheticalD = funnyKD*(startingVal - chassisOrientation)*200;
			chassisPID = hypotheticalP + hypotheticalI + hypotheticalD;
			chassisOrientation += chassisPID;
			//rotationOfChassis = rcRPM[0]+rotationScalar*chassisPID;

			rotationOfChassis = rcRPM[0] + rotationCompStab;

			/*
			xJoystickDirection = rcRPM[2]*cos(angle) - rcRPM[3]*sin(angle);
			yJoystickDirection = rcRPM[2]*sin(angle) + rcRPM[3]*cos(angle);
			int16_t hypotheticalP = funnyKP*(leftDial - chassisOrientation);
			if (hypotheticalP >= 0) {
				isNegativeRegion3 = -1;
			} else {
				isNegativeRegion3 = 1;
			}
			if (hypotheticalP != previousRegion3) {
				sumI3 = 0;
			}
			previousRegion3 = hypotheticalP;
			sumI3 += (leftDial - chassisOrientation)*0.005;
			int16_t hypotheticalI = funnyKI*(sumI3);
			int16_t hypotheticalD = funnyKD*(leftDial - chassisOrientation)*200;
			chassisPID = hypotheticalP + hypotheticalI + hypotheticalD;
			chassisOrientation += chassisPID;
			rotationOfChassis = rcRPM[0]+rotationScalar*chassisPID;
			*/

			break;
		default:
			started = 0;
			xJoystickDirection = rcRPM[2];
			yJoystickDirection = rcRPM[3];
			rotationOfChassis = rcRPM[0];
		}
		// int16_t chassisConvert = ((-1*(chassisOrientation))*3.32f)+4755;

		chassisTargetRPM.motorRPM[0] = yJoystickDirection + rotationOfChassis + xJoystickDirection;
		chassisTargetRPM.motorRPM[1] = yJoystickDirection + rotationOfChassis - xJoystickDirection;
		chassisTargetRPM.motorRPM[2] = -yJoystickDirection + rotationOfChassis - xJoystickDirection;
		chassisTargetRPM.motorRPM[3] = -yJoystickDirection + rotationOfChassis + xJoystickDirection;

		//usart_printf("%d\r\n", targetMotorRPM.motorRPM[0]);
	   // calcChassisPower = (float)power_heat_data.chassis_voltage * (float)power_heat_data.chassis_current / (float)1000000;

		//if (calcChassisPower >= 30) {
		//chassisTargetCurrent = applyPowerlimit(chassis, chassisTargetRPM, calcChassisPower);

		//CAN1_cmd_b2b(CAN_b2b_A_ID, 1, 1, 1, 1);

		float kPg = 0.1;
		float kIg = 0;
		float kDg = 0;
		if (customFiringModeSwitcher == 1) {
			burst = 1;
		} else if (customFiringModeSwitcher == 2) {
			burst = 3;
		}

		setM3508RPM(1, chassisTargetRPM.motorRPM[0], chassisPreset);
		setM3508RPM(2, chassisTargetRPM.motorRPM[1], chassisPreset);
		setM3508RPM(3, chassisTargetRPM.motorRPM[2], chassisPreset);
		setM3508RPM(4, chassisTargetRPM.motorRPM[3], chassisPreset);

		int16_t roundsPerSecond = 20;
		// Constant SHOULD BE 1.3636, 0.08
		int8_t rcSwitchToShoot = getRCswitch(0);
		if (rcSwitchToShoot == 1) {
			if (customFiringModeSwitcher == 0) {
				setM3508RPM(5, roundsPerSecond * 270, chassisPreset);
			} else {
				shooterMotor = getMotorPosition(5);
				// Resets the total rotationValue to avoid going too high
				if (resetPerStart == 0) {
					int32_t rotationTarget1 = (36860 * burst);// + shooterMotor
					rotationTarget = rotationTarget1 + shooterMotor;

					revolutions = 0;
					rotationalVal = shooterMotor;
					previousVal = shooterMotor;
				}
				resetPerStart = 1;
				posForGunMotor = kPg*(rotationTarget - rotationalVal);

				// counts the amount of rotations
				if ((shooterMotor - previousVal) < -1000) {
					 revolutions++;
				} /* else if ((shooterMotor - previousVal) > 4500) {
				revolutions --
				}
				*/
				previousVal = shooterMotor;
				rotationalVal = shooterMotor + (revolutions*8191);

				// int16_t PositionToGo = kPu*(rcVal-testmotor);
				if (posForGunMotor >= 0) {
					isNegativeRegion4 = -1;
				} else {
					isNegativeRegion4 = 1;
				}
				if (posForGunMotor != previousRegion4) {
					sumI4 = 0;
				}
				previousRegion4 = posForGunMotor;
				sumI4 += (rotationTarget-testmotor)*0.005;
				int32_t IntegralToGo4 = kIg*(sumI4);
				int32_t DerivativeToGo4 = kDg*(rotationTarget-testmotor)*200;

				int32_t finalRPM = 0;
				if ((posForGunMotor+IntegralToGo4+DerivativeToGo4) > (roundsPerSecond * 270)) {
					finalRPM =roundsPerSecond * 270;
				} else {
					finalRPM = posForGunMotor+IntegralToGo4+DerivativeToGo4;
				}
				setM3508RPM(5, finalRPM, chassisPreset);
			}
			switched = 0;
			/*
			switched = 0;
			setM3508RPM(5, roundsPerSecond * 270, chassisPreset);
			*/
			// __HAL_TIM_SET_COMPARE(&htim1, TIM_CHANNEL_1, rcVal + 252);
			// __HAL_TIM_SET_COMPARE(&htim1, TIM_CHANNEL_2, rcVal + 252);
		} else {
			resetPerStart = 0;
			setM3508RPM(5, 0, chassisPreset);
		}
		if (rcSwitchToShoot == 2 && switched == 0 && motorOn == 0) {
			motorOn = 1;
			switched = 1;
		} else if (rcSwitchToShoot == 2 && switched == 0 && motorOn == 1) {
			motorOn = 0;
			switched = 1;
		}
		if (rcSwitchToShoot == 3) {
			switched = 0;
		}

		// int16_t testingMax = getRCchannel(1)*1.15f;
		// MAX SPEED = 759
		PWMOutput(Motor, 1, 500);
		PWMOutput(Motor, 2, 500);
		//PWMInitialize(Motor, 1, )
		htim1.Instance->CCR1=200+(350*motorOn);
		htim1.Instance->CCR2=200+(350*motorOn);

		// int32_t dividedRotation = rotationalVal * 0.01f;
		// usart_printf("$%d %d %d\r\n;",rotationalVal, shooterMotor, rotationTarget);
		testmotor = getMotorPosition(6);

		// Turret Slope min, centre, max : 5573, 6161, 675s1
		// min = 5600
		// max = 6700
		//(These are ABSOLUTE MAXES)
		// Difference = 0, 589, 1178

		float kPu =0.7; // 0.005
		float kIu =0; // 0.0001
		float kDu =0.0001; // 0.0005

		int16_t rcVal = (getRCchannel(1)*0.88f)+6161;

		int16_t DifferenceBetweenCurrentAndWannabePosition = rcVal-testmotor;

		if (testmotor < 5500) {
			setGM6020voltageRPM(6, 5, DONUTMOTOR);
		} else if (testmotor > 6800) {
			setGM6020voltageRPM(6, -5, DONUTMOTOR);
		} else {

			//positionPIDByMe(int8_t &negativeRegion, int8_t &previousRegion, int16_t &differenceBetween, int16_t &integralVal float &kPVal, float &kIVal, float &kDVal);
			// positionPIDByMe(isNegativeRegion1, previousRegion1, DifferenceBetweenCurrentAndWannabePosition, sumI1, kPu, kIu, kDu);
			/*
			if (PositionToGo >= 0) {
				isNegativeRegion1 = -1;
			} else {
				isNegativeRegion1 = 1;
			}
			if (PositionToGo != previousRegion1) {
				sumI1 = 0;
			}
			previousRegion1 = isNegativeRegion1;
			sumI1 += (DifferenceBetweenCurrentAndWannabePosition)*0.005;
			int16_t PositionToGo = kPu*(DifferenceBetweenCurrentAndWannabePosition);
			int16_t IntegralToGo = kIu*(sumI1);
			int16_t DerivativeToGo = kDu*(DifferenceBetweenCurrentAndWannabePosition)*200;
			*/

			setGM6020voltageRPM(6, positionPIDByMe(&prevDiff1, &isNegativeRegion1, &previousRegion1, DifferenceBetweenCurrentAndWannabePosition, &sumI1, kPu, kIu, kDu), DONUTMOTOR);
			// usart_printf("$%d %d %d\r\n;", PositionToGo, IntegralToGo, DerivativeToGo);
		}

		// 2524-6986
		// 90 degree = 2691, 6799
		pivoter = getMotorPosition(7);
		angle = ((pivoter-4755)*0.00024343f)*3.14159265f;

		float kPr =0.08; // 0.022
		float kIr =0.000; // -0.02
		float kDr =0.009; // 0.00005

		float gyroPosition[3] = {IMU_get_gyro(x), IMU_get_gyro(y), IMU_get_gyro(z)};
		int16_t convert[3] = { (int)(gyroPosition[0]*9.549), (int)(gyroPosition[1]*(9.549)), (int)((gyroPosition[2]+((float)leftDial*(-0.008)))*(-230))};
		/*
		rotationPositionZ += gyroPosition[2]*0.2864788976;
		rotationPositionY += gyroPosition[0]*0.2864788976;
		int16_t convertY = (int)rotationPositionY;
		int16_t convertZ = (int)rotationPositionZ;
		*/
		PWMOutput(LED, 2, 500);
		PWMInitialize(LED, FR, 2, 0.9);
		if (chassisTurning == 2) {
			// rcVal2 = ((-1*(leftDial))*3.32f)+4755;
			rcVal2 = (leftDial*3.32f)+4755;
		} else {
			rcVal2 = (leftDial*3.32f)+4755;
		}

		if (pivoter <= 6799 && pivoter >= 2691) {
			// HAL_GPIO_WritePin(GPIOH, GPIO_PIN_11, 0);
			PWMOff(LED, 2);
			rotationCompStab = 0;
		} else if (pivoter > 6799) {
			// HAL_GPIO_WritePin(GPIOH, GPIO_PIN_11, 1);
			// PWMOutput(LED, 2, 500);
			rotationCompStab = -25*(pivoter-6799);
		} else {
			// HAL_GPIO_WritePin(GPIOH, GPIO_PIN_11, 1);
			// PWMOutput(LED, 2, 500);
			rotationCompStab = -25*(pivoter-2691);
		}
		//rotationCompStab
		/*
		for (int j = 0; j < average; j++) {
			averageY[average-(j)] = averageY[average-(j+1)];
		}
		averageY[0] = convert[2];

		int16_t fullAve = 0;
		float multiplyFactor = 1/average;
		for (int i = 0; i < average; i++) {
			fullAve += averageY[i];
		}
		fullAve = fullAve*0.2f;
		*/
		int16_t DiffOfTurret = rcVal2-pivoter;
		// usart_printf("$%d %d\r\n;", convert[2], fullAve);
		if (pivoter < 2300) {
			setGM6020voltageRPM(7, 5, DONUTMOTOR);
		} else if (pivoter > 6900) {
			setGM6020voltageRPM(7, -5, DONUTMOTOR);
		} else {
			/*
			if (DiffOfTurret >= 0) {
				isNegativeRegion2 = -1;
			} else {
				isNegativeRegion2 = 1;
			}
			if (isNegativeRegion2 != previousRegion2) {
				sumI2 = 0;
			}
			previousRegion2 = PositionToGo2;
			sumI2 += (DiffOfTurret)*0.005;
			int16_t PositionToGo2 = kPr*(DiffOfTurret);
			int16_t IntegralToGo2 = kIr*(sumI2);
			int16_t DerivativeToGo2 = kDr*(DiffOfTurret)*200;
			*/
			if (chassisTurning == 2) {
				setGM6020voltageRPM(7, convert[2], DONUTMOTOR);
			} else {
				setGM6020voltageRPM(7, positionPIDByMe(&prevDiff2, &isNegativeRegion2, &previousRegion2, DiffOfTurret, &sumI2, kPr, kIr, kDr), DONUTMOTOR);
			}
			// usart_printf("$%d %d\r\n;", DiffOfTurret, sumI2);
		}

		// usart_printf("$%d %d %d\r\n;", rcVal2, pivoter, chassisConvert);
		//usart_printf("$%d\r\d;", rotationOfChassis);
		// usart_printf("$%d %d\r\n;",rcVal2 ,pivoter);
		// usart_printf("$%d\r\n;",pivoter);
		// usart_printRC();

		// sendB2bData(CAN_b2b_A_motorCtrl_ID, rcPitch, 0, 0, 0);

	  /*
		if (boardID == CAN_b2b_B_ID) {
			setGM6020voltagePosition(9, b2bMotorCtrl.motor1_Ctrl, yawPresetVoltagePosition);
			//setGM6020voltageRPM(9, 100, yawPresetVoltageRPM);
			//CAN2_cmd_motors(CAN_GROUP3C_ID, 5000, 0, 0, 0);
			sendB2bData(CAN_b2b_B_gyro_ID, b2bMotorCtrl.motor1_Ctrl, getMotorPosition(9), 0, 0);
		}
	  */
		//set_GM6020_current(5, 8000);               getMotorPosition(9) getMotorCurrent(9)
		//set_GM6020_voltage(5, 2000);
		//setGM6020voltageRPM(5, 100, yawPresetVoltageRPM);
		//setGM6020currentPosition(5, target, yawPresetPosition);
		//setGM6020voltagePosition(5, target, yawPresetVoltagePosition);
		//usart_printf("%d\r\n", getMotorRPM(5));
		//usart_printRC();
		//sprintf((char*)txbuf, "%f \r\n", power_heat_data.chassis_power);
		//HAL_UART_Transmit(&huart1, txbuf, strlen((char*)txbuf), HAL_MAX_DELAY);
		//txbuf = *((float*)&power_heat_data.chassis_power);
		//usart_printf("%f %d\r\n", calcChassisPower, 30);
		/*
		uint8_t txDataBuffer = 0xff;
		HAL_UART_Transmit(&huart1, txDataBuffer,8,0);
		*/
		/*
		for(int i = 0; i < 11; i++) {
			testTHing[i] = whichPWMisOn[i];
		}
		*/
		//testTHing[11]
		// usart_printf("|  ‰d  |  ‰d  |  ‰d  |  ‰d  |  ‰d  |  ‰d  |  ‰d  |  ‰d  |  ‰d  |  ‰d  |  ‰d  |\r\n", testTHing[0], testTHing[1], testTHing[2], testTHing[3], testTHing[4], testTHing[5], testTHing[6], testTHing[7], testTHing[8], testTHing[9], testTHing[10]);
		//mainPrint();
		PWMTimerStarter();
		osDelay(5);
    }
  /* USER CODE END TaskChassis */
}

__weak void imu_temp_control_task(void *argument)
{
  for(;;)
  {
    osDelay(1);
  }
}

void TaskTurret(void *argument)
{
  for(;;)
  {
    osDelay(1);
  }
}

void Error_Handler(void)
{
  __disable_irq();
  while (1)
  {
  }
}
